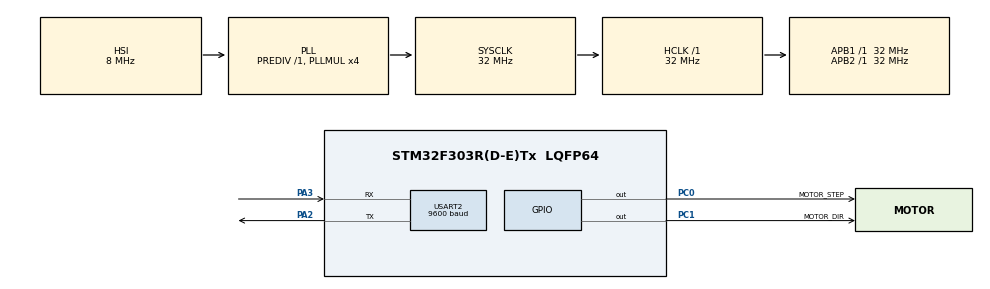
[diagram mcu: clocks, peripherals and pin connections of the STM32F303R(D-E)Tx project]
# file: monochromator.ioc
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Mcu.Family=STM32F3
Mcu.Name=STM32F303R(D-E)Tx
Mcu.Package=LQFP64
NVIC.PriorityGroup=NVIC_PRIORITYGROUP_4
NVIC.USART2_IRQn=true\:0\:0\:false\:false\:true\:true
PA2.Mode=Asynchronous
PA2.Signal=USART2_TX
PA3.Mode=Asynchronous
PA3.Signal=USART2_RX
PC0.GPIO_Label=MOTOR_STEP
PC0.Signal=GPIO_Output
PC1.GPIO_Label=MOTOR_DIR
PC1.Signal=GPIO_Output
ProjectManager.HeapSize=0x200
ProjectManager.StackSize=0x400
ProjectManager.TargetToolchain=Makefile
RCC.AHBFreq_Value=32000000
RCC.APB1Freq_Value=32000000
RCC.APB1TimFreq_Value=32000000
RCC.APB2Freq_Value=32000000
RCC.APB2TimFreq_Value=32000000
RCC.CortexFreq_Value=32000000
RCC.HCLKFreq_Value=32000000
RCC.HSE_VALUE=8000000
RCC.HSI_VALUE=8000000
RCC.LSE_VALUE=32768
RCC.PLLMUL=RCC_PLL_MUL4
RCC.SYSCLKFreq_VALUE=32000000
RCC.SYSCLKSourceVirtual=RCC_SYSCLKSOURCE_PLLCLK
RCC.USBFreq_Value=32000000
USART2.BaudRate=9600
USART2.VirtualMode-Asynchronous=VM_ASYNC
USART2.WordLength=WORDLENGTH_8B
board=monochromator

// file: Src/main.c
/**
 ******************************************************************************
 * @file           : main.c
 * @brief          : Main program body
 ******************************************************************************
 ** This notice applies to any and all portions of this file
 * that are not between comment pairs USER CODE BEGIN and
 * USER CODE END. Other portions of this file, whether
 * inserted by the user or by software development tools
 * are owned by their respective copyright owners.
 *
 * COPYRIGHT(c) 2018 STMicroelectronics
 *
 * Redistribution and use in source and binary forms, with or without modification,
 * are permitted provided that the following conditions are met:
 *   1. Redistributions of source code must retain the above copyright notice,
 *      this list of conditions and the following disclaimer.
 *   2. Redistributions in binary form must reproduce the above copyright notice,
 *      this list of conditions and the following disclaimer in the documentation
 *      and/or other materials provided with the distribution.
 *   3. Neither the name of STMicroelectronics nor the names of its contributors
 *      may be used to endorse or promote products derived from this software
 *      without specific prior written permission.
 *
 * THIS SOFTWARE IS PROVIDED BY THE COPYRIGHT HOLDERS AND CONTRIBUTORS "AS IS"
 * AND ANY EXPRESS OR IMPLIED WARRANTIES, INCLUDING, BUT NOT LIMITED TO, THE
 * IMPLIED WARRANTIES OF MERCHANTABILITY AND FITNESS FOR A PARTICULAR PURPOSE ARE
 * DISCLAIMED. IN NO EVENT SHALL THE COPYRIGHT HOLDER OR CONTRIBUTORS BE LIABLE
 * FOR ANY DIRECT, INDIRECT, INCIDENTAL, SPECIAL, EXEMPLARY, OR CONSEQUENTIAL
 * DAMAGES (INCLUDING, BUT NOT LIMITED TO, PROCUREMENT OF SUBSTITUTE GOODS OR
 * SERVICES; LOSS OF USE, DATA, OR PROFITS; OR BUSINESS INTERRUPTION) HOWEVER
 * CAUSED AND ON ANY THEORY OF LIABILITY, WHETHER IN CONTRACT, STRICT LIABILITY,
 * OR TORT (INCLUDING NEGLIGENCE OR OTHERWISE) ARISING IN ANY WAY OUT OF THE USE
 * OF THIS SOFTWARE, EVEN IF ADVISED OF THE POSSIBILITY OF SUCH DAMAGE.
 *
 ******************************************************************************
 */
#include "main.h"
#include "stm32f3xx_hal.h"

/* USER CODE BEGIN Includes */
#include "motor.h"
/* USER CODE END Includes */

UART_HandleTypeDef huart2;

/* USER CODE BEGIN PV */
/* Private variables ---------------------------------------------------------*/

/* USER CODE END PV */

void SystemClock_Config(void);
static void MX_GPIO_Init(void);
static void MX_USART2_UART_Init(void);

/* USER CODE BEGIN PFP */
/* Private function prototypes -----------------------------------------------*/

/* USER CODE END PFP */

int main(void)
{

    /* MCU Configuration----------------------------------------------------------*/

    /* Reset of all peripherals, Initializes the Flash interface and the Systick. */
    HAL_Init();

    /* Configure the system clock */
    SystemClock_Config();

    /* Initialize all configured peripherals */
    MX_GPIO_Init();
    MX_USART2_UART_Init();

    /* Infinite loop */
    while (1)
    {
        /* USER CODE BEGIN 3 */
        motor_dir_front();
        motor_steps(10000);
        motor_dir_reverse();
        motor_steps(10000);
    }
    /* USER CODE END 3 */
} /* main */

void SystemClock_Config(void)
{
    RCC_OscInitTypeDef RCC_OscInitStruct;
    RCC_ClkInitTypeDef RCC_ClkInitStruct;
    RCC_PeriphCLKInitTypeDef PeriphClkInit;

    /**Initializes the CPU, AHB and APB busses clocks
     */
    RCC_OscInitStruct.OscillatorType      = RCC_OSCILLATORTYPE_HSI;
    RCC_OscInitStruct.HSIState            = RCC_HSI_ON;
    RCC_OscInitStruct.HSICalibrationValue = 16;
    RCC_OscInitStruct.PLL.PLLState        = RCC_PLL_ON;
    RCC_OscInitStruct.PLL.PLLSource       = RCC_PLLSOURCE_HSI;
    RCC_OscInitStruct.PLL.PLLMUL          = RCC_PLL_MUL4;
    RCC_OscInitStruct.PLL.PREDIV          = RCC_PREDIV_DIV1;
    if (HAL_RCC_OscConfig(&RCC_OscInitStruct) != HAL_OK)
    {
        _Error_Handler(__FILE__, __LINE__);
    }

    /**Initializes the CPU, AHB and APB busses clocks
     */
    RCC_ClkInitStruct.ClockType = RCC_CLOCKTYPE_HCLK | RCC_CLOCKTYPE_SYSCLK
      | RCC_CLOCKTYPE_PCLK1 | RCC_CLOCKTYPE_PCLK2;
    RCC_ClkInitStruct.SYSCLKSource   = RCC_SYSCLKSOURCE_PLLCLK;
    RCC_ClkInitStruct.AHBCLKDivider  = RCC_SYSCLK_DIV1;
    RCC_ClkInitStruct.APB1CLKDivider = RCC_HCLK_DIV1;
    RCC_ClkInitStruct.APB2CLKDivider = RCC_HCLK_DIV1;

    if (HAL_RCC_ClockConfig(&RCC_ClkInitStruct, FLASH_LATENCY_1) != HAL_OK)
    {
        _Error_Handler(__FILE__, __LINE__);
    }

    PeriphClkInit.PeriphClockSelection = RCC_PERIPHCLK_USART2;
    PeriphClkInit.Usart2ClockSelection = RCC_USART2CLKSOURCE_PCLK1;
    if (HAL_RCCEx_PeriphCLKConfig(&PeriphClkInit) != HAL_OK)
    {
        _Error_Handler(__FILE__, __LINE__);
    }

    /**Configure the Systick interrupt time
     */
    HAL_SYSTICK_Config(HAL_RCC_GetHCLKFreq() / 1000);

    /**Configure the Systick
     */
    HAL_SYSTICK_CLKSourceConfig(SYSTICK_CLKSOURCE_HCLK);

    /* SysTick_IRQn interrupt configuration */
    HAL_NVIC_SetPriority(SysTick_IRQn, 0, 0);
} /* SystemClock_Config */

/* USART2 init function */
static void MX_USART2_UART_Init(void)
{
    huart2.Instance                    = USART2;
    huart2.Init.BaudRate               = 9600;
    huart2.Init.WordLength             = UART_WORDLENGTH_8B;
    huart2.Init.StopBits               = UART_STOPBITS_1;
    huart2.Init.Parity                 = UART_PARITY_NONE;
    huart2.Init.Mode                   = UART_MODE_TX_RX;
    huart2.Init.HwFlowCtl              = UART_HWCONTROL_NONE;
    huart2.Init.OverSampling           = UART_OVERSAMPLING_16;
    huart2.Init.OneBitSampling         = UART_ONE_BIT_SAMPLE_DISABLE;
    huart2.AdvancedInit.AdvFeatureInit = UART_ADVFEATURE_NO_INIT;
    if (HAL_UART_Init(&huart2) != HAL_OK)
    {
        _Error_Handler(__FILE__, __LINE__);
    }
}

/** Configure pins as
 * Analog
 * Input
 * Output
 * EVENT_OUT
 * EXTI
 */
static void MX_GPIO_Init(void)
{
    GPIO_InitTypeDef GPIO_InitStruct;

    /* GPIO Ports Clock Enable */
    __HAL_RCC_GPIOC_CLK_ENABLE();
    __HAL_RCC_GPIOA_CLK_ENABLE();

    /*Configure GPIO pin Output Level */
    HAL_GPIO_WritePin(GPIOC, MOTOR_STEP_Pin | MOTOR_DIR_Pin, GPIO_PIN_RESET);

    /*Configure GPIO pins : MOTOR_STEP_Pin MOTOR_DIR_Pin */
    GPIO_InitStruct.Pin   = MOTOR_STEP_Pin | MOTOR_DIR_Pin;
    GPIO_InitStruct.Mode  = GPIO_MODE_OUTPUT_PP;
    GPIO_InitStruct.Pull  = GPIO_NOPULL;
    GPIO_InitStruct.Speed = GPIO_SPEED_FREQ_LOW;
    HAL_GPIO_Init(GPIOC, &GPIO_InitStruct);
}

void _Error_Handler(char *file, int line)
{
    /* USER CODE BEGIN Error_Handler_Debug */
    /* User can add his own implementation to report the HAL error return state */
    while (1)
    { }
    /* USER CODE END Error_Handler_Debug */
}

#ifdef  USE_FULL_ASSERT

/**
 * @brief  Reports the name of the source file and the source line number
 *         where the assert_param error has occurred.
 * @param  file: pointer to the source file name
 * @param  line: assert_param error line source number
 * @retval None
 */
void assert_failed(uint8_t *file, uint32_t line)
{
    /* USER CODE BEGIN 6 */

    /* User can add his own implementation to report the file name and line number,
     * tex: printf("Wrong parameters value: file %s on line %d\r\n", file, line) */
    /* USER CODE END 6 */
}

#endif /* USE_FULL_ASSERT */

/************************ (C) COPYRIGHT STMicroelectronics *****END OF FILE****/
